# LPC81x register map
Vendor: nxp.com; File version: 1.0
CPU: CM0PLUS r0p0, little endian, no MPU, no FPU, VTOR, 2 interrupt priority bits
Registers are 32-bit, read-write, reset 0x0 unless marked. A register's access mark holds for its fields unless they carry their own. Offsets are from the block's base; [hi:lo] are bit positions; {n}, {i} and the like mark numbered series.

## WKT — Wake Up Timer(WKT)
Base 0x40008000
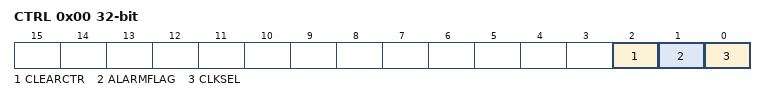
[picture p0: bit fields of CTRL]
0x00 CTRL — Self wake-up timer control register.
  [2] CLEARCTR — Clears the self wake-up timer.
    0=NO_EFFECT (No effect. Reading this bit always returns 0.); 1=CLEAR_THE_COUNTER (Clear the counter. Counting is halted until a new count value is loaded.)
  [1] ALARMFLAG — Wake-up or alarm timer flag.
    0=NO_TIME_OUT (No time-out. The self wake-up timer has not timed out. Writing a 0 to has no effect.); 1=TIME_OUT (Time-out. The self wake-up timer has timed out. This flag generates an interrupt request which can wake up the part from any reduced power mode including Deep power-down if the clock source is the low power oscillator. Writing a 1 clears this status bit.)
  [0] CLKSEL — Select the self wake-up timer clock source. Remark: This bit only has an effect if the SEL_EXTCLK bit is not set.
    0=DIVIDED_IRC_CLOCK (Divided IRC clock. This clock runs at 750 kHz and provides time-out periods of up to approximately 95 minutes in 1.33 us increments. Remark: This clock is not available in not available in Deep-sleep, power-down, deep power-down modes. Do not select this option if the timer is to be used to wake up from one of these modes.); 1=LOW_POWER_CLOCK (This is the (nominally) 10 kHz clock and provides time-out periods of up to approximately 119 hours in 100 us increments. The accuracy of this clock is limited to +/- 40 % over temperature and processing. Remark: This clock is available in all power modes. Prior to use, the low-power oscillator must be enabled. The oscillator must also be set to remain active in Deep power-down if needed.)
0x0C COUNT reset not defined — Counter register.
  [31:0] VALUE — A write to this register pre-loads start count value into the timer and starts the count-down sequence. A read reflects the current value of the timer.

## PMU
Base 0x40020000
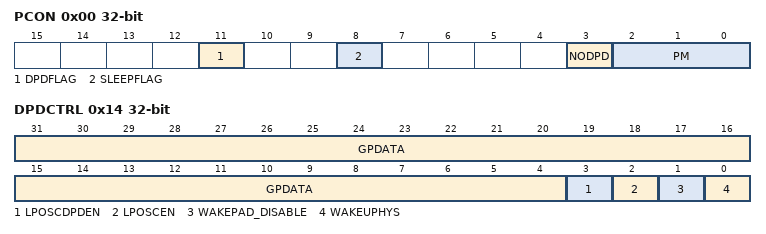
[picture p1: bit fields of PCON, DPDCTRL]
0x00 PCON — Power control register
  [11] DPDFLAG — Deep power-down flag
    0=NOT_DEEP_POWER_DOWN (Not Deep power-down. Read: Deep power-down mode not entered. Write: No effect.); 1=DEEP_POWER_DOWN (Deep power-down. Read: Deep power-down mode entered. Write: Clear the Deep power-down flag.)
  [8] SLEEPFLAG — Sleep mode flag
    0=ACTIVE_MODE (Active mode. Read: No power-down mode entered. Part is in Active mode. Write: No effect.); 1=LOW_POWER_MODE (Low power mode. Read: Sleep, Deep-sleep or Power-down mode entered. Write: Writing a 1 clears the SLEEPFLAG bit to 0.)
  [3] NODPD — A 1 in this bit prevents entry to Deep power-down mode when 0x3 is written to the PM field above, the SLEEPDEEP bit is set, and a WFI is executed. This bit is cleared only by power-on reset, so writing a one to this bit locks the part in a mode in which Deep power-down mode is blocked.
  [2:0] PM — Power mode
    0=DEFAULT (Default. The part is in active or sleep mode.); 1=DEEP_SLEEP_MODE (Deep-sleep mode. ARM WFI will enter Deep-sleep mode.); 2=POWER_DOWN_MODE (Power-down mode. ARM WFI will enter Power-down mode.); 3=DEEP_POWER_DOWN_MODE (Deep power-down mode. ARM WFI will enter Deep-power down mode (ARM Cortex-M0+ core powered-down).)
{0x4+4i} GPREG[{i}] (i=0..3) — General purpose register N
  [31:0] GPDATA — Data retained during Deep power-down mode.
0x14 DPDCTRL — Deep power-down control register. Also includes bits for general purpose storage.
  [31:4] GPDATA — Data retained during Deep power-down mode.
  [3] LPOSCDPDEN — causes the low-power oscillator to remain running during Deep power-down mode provided that bit 2 in this register is set as well. You must set this bit for the self wake-up timer to be able to wake up the part from Deep power-down mode. Remark: Do not set this bit unless you use the self wake-up timer with the low-power oscillator clock source to wake up from Deep power-down mode.
    0=DISABLED; 1=ENABLED
  [2] LPOSCEN — Enable the low-power oscillator for use with the 10 kHz self wake-up timer clock. You must set this bit if the CLKSEL bit in the self wake-up timer CTRL bit is set. Do not enable the low-power oscillator if the self wake-up timer is clocked by the divided IRC or the external clock input.
    0=DISABLED; 1=ENABLED
  [1] WAKEPAD_DISABLE — WAKEUP pin disable. Setting this bit disables the wake-up pin, so it can be used for other purposes. Remark: Never set this bit if you intend to use a pin to wake up the part from Deep power-down mode. You can only disable the wake-up pin if the self wake-up timer is enabled and configured. Remark: Setting this bit is not necessary if Deep power-down mode is not used.
    0=ENABLED (Enabled. The wake-up function is enabled on pin PIO0_4.); 1=DISABLED (Disabled. Setting this bit disables the wake-up function on pin PIO0_4.)
  [0] WAKEUPHYS — WAKEUP pin hysteresis enable
    0=DISABLED (Disabled. Hysteresis for WAKEUP pin disabled.); 1=ENABLED (Enabled. Hysteresis for WAKEUP pin enabled.)

## Notices in the file
Copyright 2016-2019 NXP
All rights reserved.
SPDX-License-Identifier: BSD-3-Clause
